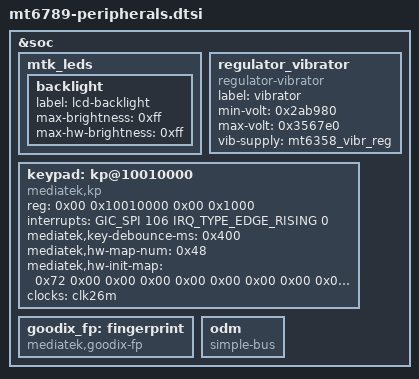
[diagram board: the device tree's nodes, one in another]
// SPDX-License-Identifier: (GPL-2.0 OR MIT)
/* MT6789 peripherals blocks -- split out of the SoC node, one subsystem per file. */

&soc {
	mtk_leds: mtk_leds {

		backlight {
			label = "lcd-backlight";
			max-brightness = <0xff>;
			max-hw-brightness = <0xff>;
		};
	};

	regulator_vibrator: regulator_vibrator {
		compatible = "regulator-vibrator";
		label = "vibrator";
		min-volt = <0x2ab980>;
		max-volt = <0x3567e0>;
		vib-supply = <&mt6358_vibr_reg>;
	};

	keypad: kp@10010000 {
		compatible = "mediatek,kp";
		reg = <0x00 0x10010000 0x00 0x1000>;
		interrupts = <GIC_SPI 106 IRQ_TYPE_EDGE_RISING 0>;
		mediatek,key-debounce-ms = <0x400>;
		mediatek,hw-map-num = <0x48>;
		mediatek,hw-init-map = <0x72 0x00 0x00 0x00 0x00 0x00 0x00 0x00 0x00 0x00 0x00 0x00 0x00 0x00 0x00 0x00 0x00 0x00 0x00 0x00 0x00 0x00 0x00 0x00 0x00 0x00 0x00 0x00 0x00 0x00 0x00 0x00 0x00 0x00 0x00 0x00 0x00 0x00 0x00 0x00 0x00 0x00 0x00 0x00 0x00 0x00 0x00 0x00 0x00 0x00 0x00 0x00 0x00 0x00 0x00 0x00 0x00 0x00 0x00 0x00 0x00 0x00 0x00 0x00 0x00 0x00 0x00 0x00 0x00 0x00 0x00 0x00>;
		clocks = <&clk26m>;
		clock-names = "kpd";
	};

	goodix_fp: fingerprint {
		compatible = "mediatek,goodix-fp";
	};

	odm: odm {
		compatible = "simple-bus";
	};

};
